VERSION ""

NS_ :

BS_:

BU_:

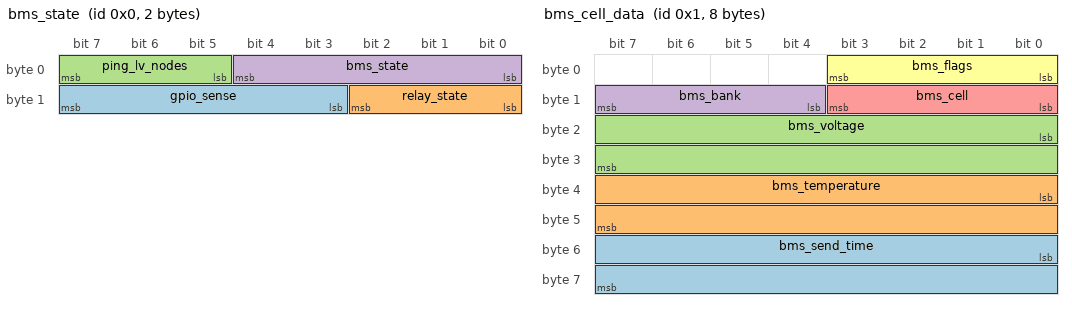
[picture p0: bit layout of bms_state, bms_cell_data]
BO_ 0 bms_state: 2 Vector__XXX
 SG_ gpio_sense : 11|5@1+ (1,0) [0|0] "" Vector__XXX
 SG_ relay_state : 8|3@1+ (1,0) [0|0] "" Vector__XXX
 SG_ ping_lv_nodes : 5|3@1+ (1,0) [0|0] "" Vector__XXX
 SG_ bms_state : 0|5@1+ (1,0) [0|0] "" Vector__XXX

BO_ 1 bms_cell_data: 8 Vector__XXX
 SG_ bms_send_time : 48|16@1+ (1,0) [0|0] "" Vector__XXX
 SG_ bms_temperature : 32|16@1- (1,0) [0|0] "" Vector__XXX
 SG_ bms_voltage : 16|16@1+ (1,0) [0|0] "" Vector__XXX
 SG_ bms_bank : 12|4@1+ (1,0) [0|0] "" Vector__XXX
 SG_ bms_cell : 8|4@1+ (1,0) [0|0] "" Vector__XXX
 SG_ bms_flags : 0|4@1+ (1,0) [0|0] "" Vector__XXX

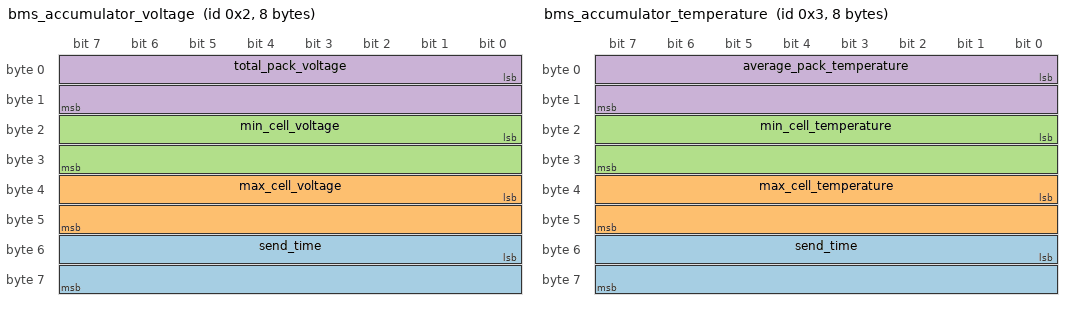
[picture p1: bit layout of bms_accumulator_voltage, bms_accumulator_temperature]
BO_ 2 bms_accumulator_voltage: 8 Vector__XXX
 SG_ send_time : 48|16@1+ (1,0) [0|0] "" Vector__XXX
 SG_ max_cell_voltage : 32|16@1+ (1,0) [0|0] "" Vector__XXX
 SG_ min_cell_voltage : 16|16@1+ (1,0) [0|0] "" Vector__XXX
 SG_ total_pack_voltage : 0|16@1+ (1,0) [0|0] "" Vector__XXX

BO_ 3 bms_accumulator_temperature: 8 Vector__XXX
 SG_ send_time : 48|16@1+ (1,0) [0|0] "" Vector__XXX
 SG_ max_cell_temperature : 32|16@1- (1,0) [0|0] "" Vector__XXX
 SG_ min_cell_temperature : 16|16@1- (1,0) [0|0] "" Vector__XXX
 SG_ average_pack_temperature : 0|16@1- (1,0) [0|0] "" Vector__XXX

BO_ 4 accumulator_faults: 1 Vector__XXX
 SG_ imd_fault : 1|1@1+ (1,0) [0|0] "" Vector__XXX
 SG_ bms_fault : 0|1@1+ (1,0) [0|0] "" Vector__XXX

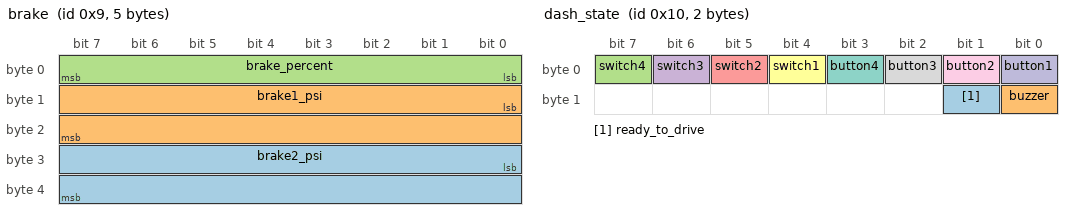
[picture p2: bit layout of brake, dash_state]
BO_ 9 brake: 5 Vector__XXX
 SG_ brake2_psi : 24|16@1+ (1,0) [0|0] "" Vector__XXX
 SG_ brake1_psi : 8|16@1+ (1,0) [0|0] "" Vector__XXX
 SG_ brake_percent : 0|8@1+ (1,0) [0|0] "" Vector__XXX

BO_ 10 bspd_state: 1 Vector__XXX
 SG_ bspd_state : 0|8@1+ (1,0) [0|0] "" Vector__XXX

BO_ 16 dash_state: 2 Vector__XXX
 SG_ ready_to_drive : 9|1@1+ (1,0) [0|0] "" Vector__XXX
 SG_ buzzer : 8|1@1+ (1,0) [0|0] "" Vector__XXX
 SG_ switch4 : 7|1@1+ (1,0) [0|0] "" Vector__XXX
 SG_ switch3 : 6|1@1+ (1,0) [0|0] "" Vector__XXX
 SG_ switch2 : 5|1@1+ (1,0) [0|0] "" Vector__XXX
 SG_ switch1 : 4|1@1+ (1,0) [0|0] "" Vector__XXX
 SG_ button4 : 3|1@1+ (1,0) [0|0] "" Vector__XXX
 SG_ button3 : 2|1@1+ (1,0) [0|0] "" Vector__XXX
 SG_ button2 : 1|1@1+ (1,0) [0|0] "" Vector__XXX
 SG_ button1 : 0|1@1+ (1,0) [0|0] "" Vector__XXX

BO_ 22 lvpdb_lv_24v_bus_and_12v_bus_vol: 4 Vector__XXX
 SG_ lv_12v_voltage : 16|16@1+ (1,0) [0|0] "" Vector__XXX
 SG_ lv_24v_voltage : 0|16@1+ (1,0) [0|0] "" Vector__XXX

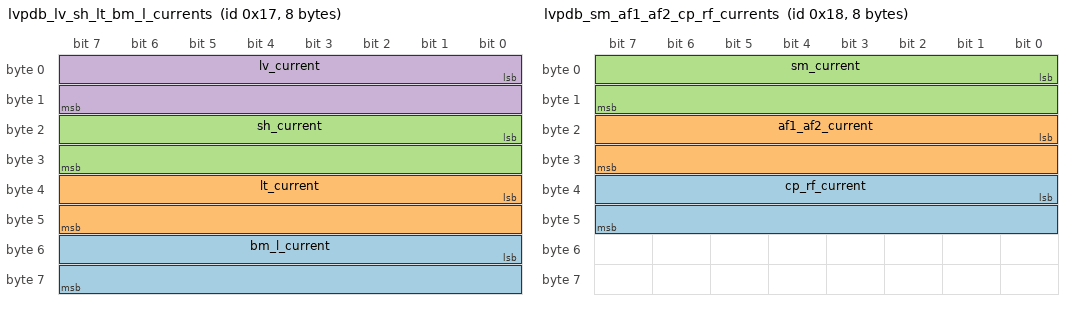
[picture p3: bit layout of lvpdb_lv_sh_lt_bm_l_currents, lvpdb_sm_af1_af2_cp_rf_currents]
BO_ 23 lvpdb_lv_sh_lt_bm_l_currents: 8 Vector__XXX
 SG_ bm_l_current : 48|16@1+ (1,0) [0|0] "" Vector__XXX
 SG_ lt_current : 32|16@1+ (1,0) [0|0] "" Vector__XXX
 SG_ sh_current : 16|16@1+ (1,0) [0|0] "" Vector__XXX
 SG_ lv_current : 0|16@1+ (1,0) [0|0] "" Vector__XXX

BO_ 24 lvpdb_sm_af1_af2_cp_rf_currents: 8 Vector__XXX
 SG_ cp_rf_current : 32|16@1+ (1,0) [0|0] "" Vector__XXX
 SG_ af1_af2_current : 16|16@1+ (1,0) [0|0] "" Vector__XXX
 SG_ sm_current : 0|16@1+ (1,0) [0|0] "" Vector__XXX

BO_ 30 linear_potentiometer_front: 4 Vector__XXX
 SG_ linear_potrentiometer_2_front : 16|16@1+ (1,0) [0|0] "" Vector__XXX
 SG_ linear_potrentiometer_1_front : 0|16@1+ (1,0) [0|0] "" Vector__XXX

BO_ 31 linear_potentiometer_rear: 4 Vector__XXX
 SG_ linear_potrentiometer_2_rear : 16|16@1+ (1,0) [0|0] "" Vector__XXX
 SG_ linear_potrentiometer_1_rear : 0|16@1+ (1,0) [0|0] "" Vector__XXX

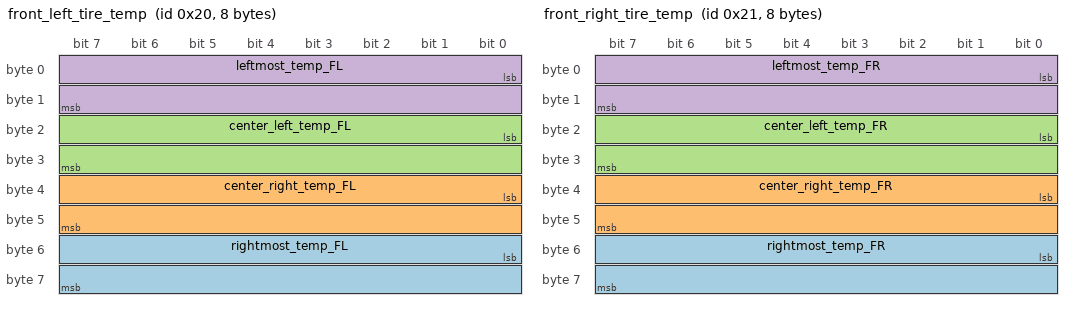
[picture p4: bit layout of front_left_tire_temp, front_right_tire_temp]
BO_ 32 front_left_tire_temp: 8 Vector__XXX
 SG_ rightmost_temp_FL : 48|16@1+ (1,0) [0|0] "" Vector__XXX
 SG_ center_right_temp_FL : 32|16@1+ (1,0) [0|0] "" Vector__XXX
 SG_ center_left_temp_FL : 16|16@1+ (1,0) [0|0] "" Vector__XXX
 SG_ leftmost_temp_FL : 0|16@1+ (1,0) [0|0] "" Vector__XXX

BO_ 33 front_right_tire_temp: 8 Vector__XXX
 SG_ rightmost_temp_FR : 48|16@1+ (1,0) [0|0] "" Vector__XXX
 SG_ center_right_temp_FR : 32|16@1+ (1,0) [0|0] "" Vector__XXX
 SG_ center_left_temp_FR : 16|16@1+ (1,0) [0|0] "" Vector__XXX
 SG_ leftmost_temp_FR : 0|16@1+ (1,0) [0|0] "" Vector__XXX

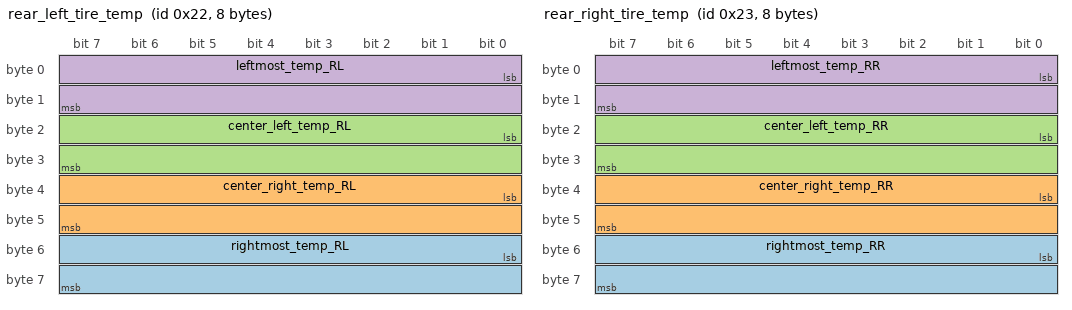
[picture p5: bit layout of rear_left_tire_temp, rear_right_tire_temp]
BO_ 34 rear_left_tire_temp: 8 Vector__XXX
 SG_ rightmost_temp_RL : 48|16@1+ (1,0) [0|0] "" Vector__XXX
 SG_ center_right_temp_RL : 32|16@1+ (1,0) [0|0] "" Vector__XXX
 SG_ center_left_temp_RL : 16|16@1+ (1,0) [0|0] "" Vector__XXX
 SG_ leftmost_temp_RL : 0|16@1+ (1,0) [0|0] "" Vector__XXX

BO_ 35 rear_right_tire_temp: 8 Vector__XXX
 SG_ rightmost_temp_RR : 48|16@1+ (1,0) [0|0] "" Vector__XXX
 SG_ center_right_temp_RR : 32|16@1+ (1,0) [0|0] "" Vector__XXX
 SG_ center_left_temp_RR : 16|16@1+ (1,0) [0|0] "" Vector__XXX
 SG_ leftmost_temp_RR : 0|16@1+ (1,0) [0|0] "" Vector__XXX

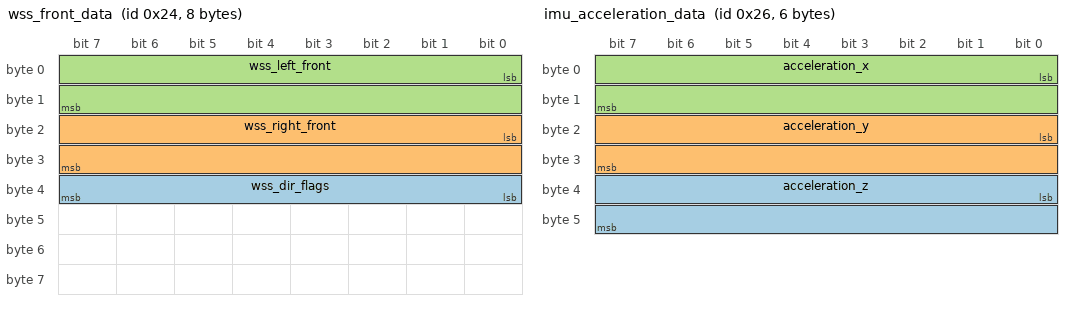
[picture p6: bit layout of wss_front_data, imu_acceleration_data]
BO_ 36 wss_front_data: 8 Vector__XXX
 SG_ wss_dir_flags : 32|8@1+ (1,0) [0|0] "" Vector__XXX
 SG_ wss_right_front : 16|16@1+ (0.1,0) [0|0] "RPM" Vector__XXX
 SG_ wss_left_front : 0|16@1+ (0.1,0) [0|0] "RPM" Vector__XXX

BO_ 37 wss_rear_data: 8 Vector__XXX
 SG_ wss_left_rear : 32|32@1+ (1,0) [0|0] "" Vector__XXX
 SG_ wss_right_rear : 0|32@1+ (1,0) [0|0] "" Vector__XXX

BO_ 38 imu_acceleration_data: 6 Vector__XXX
 SG_ acceleration_z : 32|16@1- (0.061,0) [0|0] "mg" Vector__XXX
 SG_ acceleration_y : 16|16@1- (0.061,0) [0|0] "mg" Vector__XXX
 SG_ acceleration_x : 0|16@1- (0.061,0) [0|0] "mg" Vector__XXX

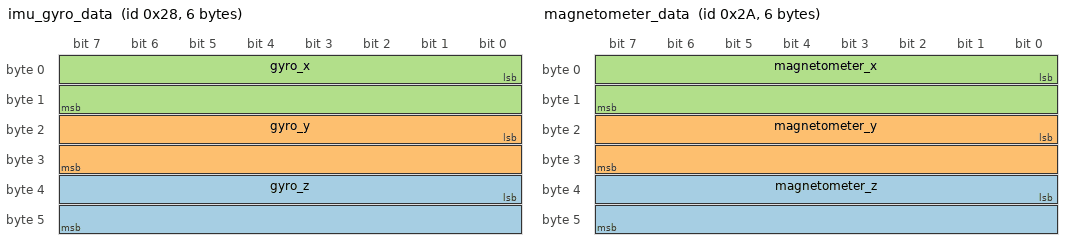
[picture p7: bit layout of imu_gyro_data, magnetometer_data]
BO_ 40 imu_gyro_data: 6 Vector__XXX
 SG_ gyro_z : 32|16@1- (70,0) [0|0] "mdps" Vector__XXX
 SG_ gyro_y : 16|16@1- (70,0) [0|0] "mdps" Vector__XXX
 SG_ gyro_x : 0|16@1- (70,0) [0|0] "mdps" Vector__XXX

BO_ 42 magnetometer_data: 6 Vector__XXX
 SG_ magnetometer_z : 32|16@1- (0.5844,0) [0|0] "mG" Vector__XXX
 SG_ magnetometer_y : 16|16@1- (0.5844,0) [0|0] "mG" Vector__XXX
 SG_ magnetometer_x : 0|16@1- (0.5844,0) [0|0] "mG" Vector__XXX

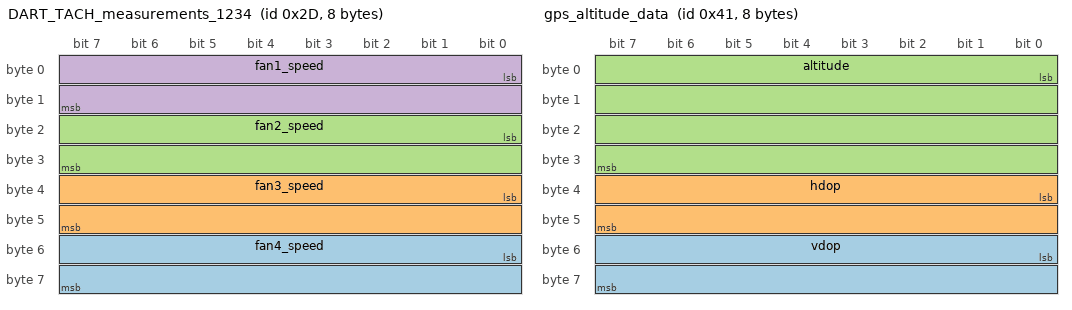
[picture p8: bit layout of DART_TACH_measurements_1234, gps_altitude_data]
BO_ 45 DART_TACH_measurements_1234: 8 Vector__XXX
 SG_ fan4_speed : 48|16@1+ (1,0) [0|0] "" Vector__XXX
 SG_ fan3_speed : 32|16@1+ (1,0) [0|0] "" Vector__XXX
 SG_ fan2_speed : 16|16@1+ (1,0) [0|0] "" Vector__XXX
 SG_ fan1_speed : 0|16@1+ (1,0) [0|0] "" Vector__XXX

BO_ 46 DART_TACH_measurements_5: 2 Vector__XXX
 SG_ fan5_speed : 0|16@1+ (1,0) [0|0] "" Vector__XXX

BO_ 52 bbb_tps: 4 Vector__XXX
 SG_ current : 16|16@1+ (1,0) [0|0] "" Vector__XXX
 SG_ voltage : 0|16@1+ (1,0) [0|0] "" Vector__XXX

BO_ 53 pcu_tps: 4 Vector__XXX
 SG_ current : 16|16@1+ (1,0) [0|0] "" Vector__XXX
 SG_ voltage : 0|16@1+ (1,0) [0|0] "" Vector__XXX

BO_ 54 dash_tps: 4 Vector__XXX
 SG_ current : 16|16@1+ (1,0) [0|0] "" Vector__XXX
 SG_ voltage : 0|16@1+ (1,0) [0|0] "" Vector__XXX

BO_ 55 dcu_tps: 4 Vector__XXX
 SG_ current : 16|16@1+ (1,0) [0|0] "" Vector__XXX
 SG_ voltage : 0|16@1+ (1,0) [0|0] "" Vector__XXX

BO_ 64 gps_pos_data: 8 Vector__XXX
 SG_ longitude : 32|32@1- (1e-07,0) [0|0] "deg" Vector__XXX
 SG_ latitude : 0|32@1- (1e-07,0) [0|0] "deg" Vector__XXX

BO_ 65 gps_altitude_data: 8 Vector__XXX
 SG_ vdop : 48|16@1+ (0.01,0) [0|0] "" Vector__XXX
 SG_ hdop : 32|16@1+ (0.01,0) [0|0] "" Vector__XXX
 SG_ altitude : 0|32@1- (0.01,0) [0|0] "m" Vector__XXX

BO_ 66 gps_motion_data: 4 Vector__XXX
 SG_ course : 16|16@1+ (0.01,0) [0|0] "deg" Vector__XXX
 SG_ speed : 0|16@1+ (0.01,0) [0|0] "km/h" Vector__XXX

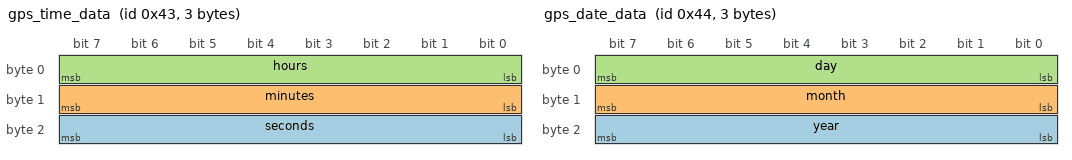
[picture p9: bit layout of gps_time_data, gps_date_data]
BO_ 67 gps_time_data: 3 Vector__XXX
 SG_ seconds : 16|8@1- (1,0) [0|0] "" Vector__XXX
 SG_ minutes : 8|8@1- (1,0) [0|0] "" Vector__XXX
 SG_ hours : 0|8@1- (1,0) [0|0] "" Vector__XXX

BO_ 68 gps_date_data: 3 Vector__XXX
 SG_ year : 16|8@1- (1,0) [0|0] "" Vector__XXX
 SG_ month : 8|8@1- (1,0) [0|0] "" Vector__XXX
 SG_ day : 0|8@1- (1,0) [0|0] "" Vector__XXX

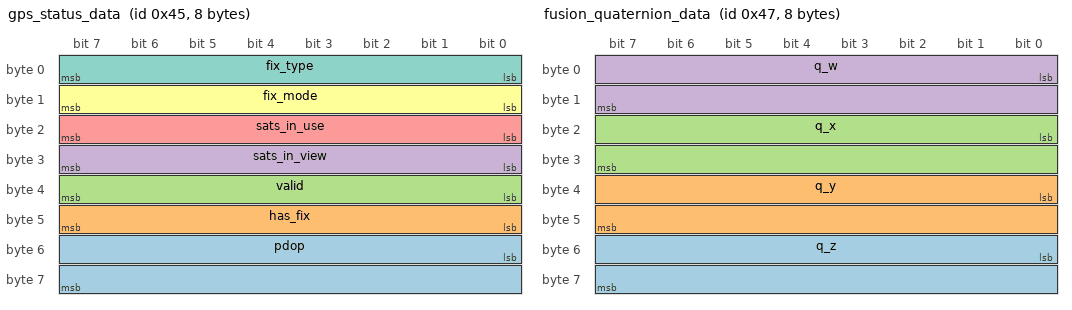
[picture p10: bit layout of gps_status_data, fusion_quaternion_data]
BO_ 69 gps_status_data: 8 Vector__XXX
 SG_ pdop : 48|16@1+ (0.01,0) [0|0] "" Vector__XXX
 SG_ has_fix : 40|8@1+ (1,0) [0|0] "" Vector__XXX
 SG_ valid : 32|8@1+ (1,0) [0|0] "" Vector__XXX
 SG_ sats_in_view : 24|8@1+ (1,0) [0|0] "" Vector__XXX
 SG_ sats_in_use : 16|8@1+ (1,0) [0|0] "" Vector__XXX
 SG_ fix_mode : 8|8@1+ (1,0) [0|0] "" Vector__XXX
 SG_ fix_type : 0|8@1+ (1,0) [0|0] "" Vector__XXX

BO_ 71 fusion_quaternion_data: 8 Vector__XXX
 SG_ q_z : 48|16@1- (3.051850947599719e-05,0) [0|0] "" Vector__XXX
 SG_ q_y : 32|16@1- (3.051850947599719e-05,0) [0|0] "" Vector__XXX
 SG_ q_x : 16|16@1- (3.051850947599719e-05,0) [0|0] "" Vector__XXX
 SG_ q_w : 0|16@1- (3.051850947599719e-05,0) [0|0] "" Vector__XXX

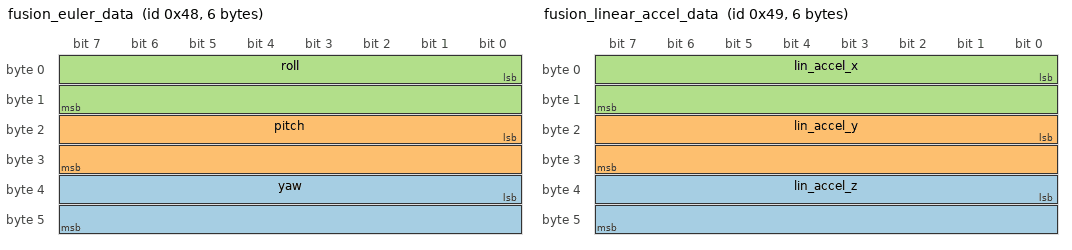
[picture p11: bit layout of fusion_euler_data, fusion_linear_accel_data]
BO_ 72 fusion_euler_data: 6 Vector__XXX
 SG_ yaw : 32|16@1- (0.01,0) [0|0] "deg" Vector__XXX
 SG_ pitch : 16|16@1- (0.01,0) [0|0] "deg" Vector__XXX
 SG_ roll : 0|16@1- (0.01,0) [0|0] "deg" Vector__XXX

BO_ 73 fusion_linear_accel_data: 6 Vector__XXX
 SG_ lin_accel_z : 32|16@1- (1,0) [0|0] "mg" Vector__XXX
 SG_ lin_accel_y : 16|16@1- (1,0) [0|0] "mg" Vector__XXX
 SG_ lin_accel_x : 0|16@1- (1,0) [0|0] "mg" Vector__XXX

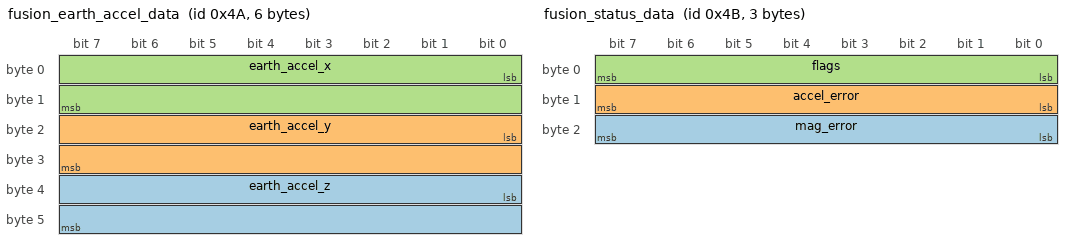
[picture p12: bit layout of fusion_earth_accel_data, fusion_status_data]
BO_ 74 fusion_earth_accel_data: 6 Vector__XXX
 SG_ earth_accel_z : 32|16@1- (1,0) [0|0] "mg" Vector__XXX
 SG_ earth_accel_y : 16|16@1- (1,0) [0|0] "mg" Vector__XXX
 SG_ earth_accel_x : 0|16@1- (1,0) [0|0] "mg" Vector__XXX

BO_ 75 fusion_status_data: 3 Vector__XXX
 SG_ mag_error : 16|8@1+ (0.1,0) [0|0] "deg" Vector__XXX
 SG_ accel_error : 8|8@1+ (0.1,0) [0|0] "deg" Vector__XXX
 SG_ flags : 0|8@1+ (1,0) [0|0] "" Vector__XXX

BO_ 76 sensor_temps_data: 4 Vector__XXX
 SG_ mag_temp : 16|16@1- (0.01,0) [0|0] "degC" Vector__XXX
 SG_ imu_temp : 0|16@1- (0.01,0) [0|0] "degC" Vector__XXX

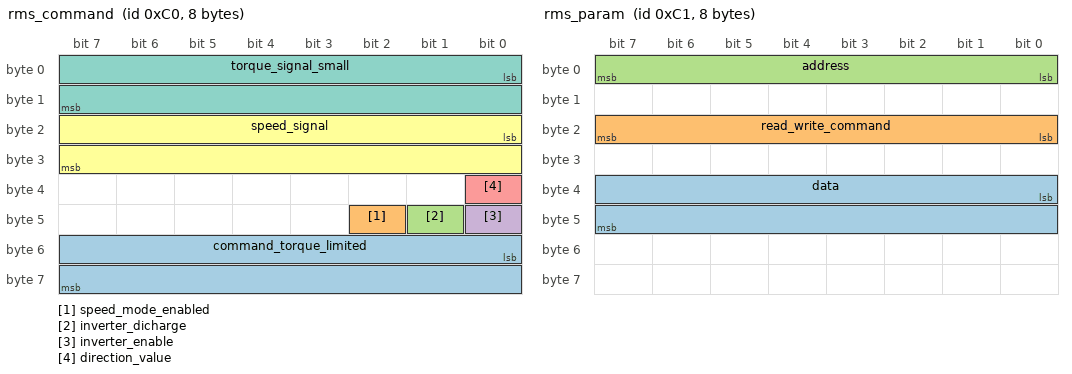
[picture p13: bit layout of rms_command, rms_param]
BO_ 192 rms_command: 8 Vector__XXX
 SG_ command_torque_limited : 48|16@1+ (1,0) [0|0] "" Vector__XXX
 SG_ speed_mode_enabled : 42|1@1+ (1,0) [0|0] "" Vector__XXX
 SG_ inverter_dicharge : 41|1@1+ (1,0) [0|0] "" Vector__XXX
 SG_ inverter_enable : 40|1@1+ (1,0) [0|0] "" Vector__XXX
 SG_ direction_value : 32|1@1+ (1,0) [0|0] "" Vector__XXX
 SG_ speed_signal : 16|16@1+ (1,0) [0|0] "" Vector__XXX
 SG_ torque_signal_small : 0|16@1+ (1,0) [0|0] "" Vector__XXX

BO_ 193 rms_param: 8 Vector__XXX
 SG_ data : 32|16@1+ (1,0) [0|0] "" Vector__XXX
 SG_ read_write_command : 16|8@1+ (1,0) [0|0] "" Vector__XXX
 SG_ address : 0|8@1+ (1,0) [0|0] "" Vector__XXX

BO_ 208 pcu_heartbeat: 8 Vector__XXX
 SG_ error63 : 63|1@1+ (1,0) [0|0] "" Vector__XXX
 SG_ error62 : 62|1@1+ (1,0) [0|0] "" Vector__XXX
 SG_ error61 : 61|1@1+ (1,0) [0|0] "" Vector__XXX
 SG_ error60 : 60|1@1+ (1,0) [0|0] "" Vector__XXX
 SG_ error59 : 59|1@1+ (1,0) [0|0] "" Vector__XXX
 SG_ error58 : 58|1@1+ (1,0) [0|0] "" Vector__XXX
 SG_ error57 : 57|1@1+ (1,0) [0|0] "" Vector__XXX
 SG_ error56 : 56|1@1+ (1,0) [0|0] "" Vector__XXX
 SG_ error55 : 55|1@1+ (1,0) [0|0] "" Vector__XXX
 SG_ error54 : 54|1@1+ (1,0) [0|0] "" Vector__XXX
 SG_ error53 : 53|1@1+ (1,0) [0|0] "" Vector__XXX
 SG_ error52 : 52|1@1+ (1,0) [0|0] "" Vector__XXX
 SG_ error51 : 51|1@1+ (1,0) [0|0] "" Vector__XXX
 SG_ error50 : 50|1@1+ (1,0) [0|0] "" Vector__XXX
 SG_ error49 : 49|1@1+ (1,0) [0|0] "" Vector__XXX
 SG_ error48 : 48|1@1+ (1,0) [0|0] "" Vector__XXX
 SG_ error47 : 47|1@1+ (1,0) [0|0] "" Vector__XXX
 SG_ error46 : 46|1@1+ (1,0) [0|0] "" Vector__XXX
 SG_ error45 : 45|1@1+ (1,0) [0|0] "" Vector__XXX
 SG_ error44 : 44|1@1+ (1,0) [0|0] "" Vector__XXX
 SG_ error43 : 43|1@1+ (1,0) [0|0] "" Vector__XXX
 SG_ error42 : 42|1@1+ (1,0) [0|0] "" Vector__XXX
 SG_ error41 : 41|1@1+ (1,0) [0|0] "" Vector__XXX
 SG_ error40 : 40|1@1+ (1,0) [0|0] "" Vector__XXX
 SG_ error39 : 39|1@1+ (1,0) [0|0] "" Vector__XXX
 SG_ error38 : 38|1@1+ (1,0) [0|0] "" Vector__XXX
 SG_ error37 : 37|1@1+ (1,0) [0|0] "" Vector__XXX
 SG_ error36 : 36|1@1+ (1,0) [0|0] "" Vector__XXX
 SG_ error35 : 35|1@1+ (1,0) [0|0] "" Vector__XXX
 SG_ error34 : 34|1@1+ (1,0) [0|0] "" Vector__XXX
 SG_ error33 : 33|1@1+ (1,0) [0|0] "" Vector__XXX
 SG_ error32 : 32|1@1+ (1,0) [0|0] "" Vector__XXX
 SG_ error31 : 31|1@1+ (1,0) [0|0] "" Vector__XXX
 SG_ error30 : 30|1@1+ (1,0) [0|0] "" Vector__XXX
 SG_ error29 : 29|1@1+ (1,0) [0|0] "" Vector__XXX
 SG_ error28 : 28|1@1+ (1,0) [0|0] "" Vector__XXX
 SG_ error27 : 27|1@1+ (1,0) [0|0] "" Vector__XXX
 SG_ error26 : 26|1@1+ (1,0) [0|0] "" Vector__XXX
 SG_ error25 : 25|1@1+ (1,0) [0|0] "" Vector__XXX
 SG_ error24 : 24|1@1+ (1,0) [0|0] "" Vector__XXX
 SG_ error23 : 23|1@1+ (1,0) [0|0] "" Vector__XXX
 SG_ error22 : 22|1@1+ (1,0) [0|0] "" Vector__XXX
 SG_ error21 : 21|1@1+ (1,0) [0|0] "" Vector__XXX
 SG_ error20 : 20|1@1+ (1,0) [0|0] "" Vector__XXX
 SG_ error19 : 19|1@1+ (1,0) [0|0] "" Vector__XXX
 SG_ error18 : 18|1@1+ (1,0) [0|0] "" Vector__XXX
 SG_ error17 : 17|1@1+ (1,0) [0|0] "" Vector__XXX
 SG_ error16 : 16|1@1+ (1,0) [0|0] "" Vector__XXX
 SG_ error15 : 15|1@1+ (1,0) [0|0] "" Vector__XXX
 SG_ error14 : 14|1@1+ (1,0) [0|0] "" Vector__XXX
 SG_ error13 : 13|1@1+ (1,0) [0|0] "" Vector__XXX
 SG_ error12 : 12|1@1+ (1,0) [0|0] "" Vector__XXX
 SG_ error11 : 11|1@1+ (1,0) [0|0] "" Vector__XXX
 SG_ error10 : 10|1@1+ (1,0) [0|0] "" Vector__XXX
 SG_ error9 : 9|1@1+ (1,0) [0|0] "" Vector__XXX
 SG_ error8 : 8|1@1+ (1,0) [0|0] "" Vector__XXX
 SG_ error7 : 7|1@1+ (1,0) [0|0] "" Vector__XXX
 SG_ error6 : 6|1@1+ (1,0) [0|0] "" Vector__XXX
 SG_ error5 : 5|1@1+ (1,0) [0|0] "" Vector__XXX
 SG_ error4 : 4|1@1+ (1,0) [0|0] "" Vector__XXX
 SG_ error3 : 3|1@1+ (1,0) [0|0] "" Vector__XXX
 SG_ error2 : 2|1@1+ (1,0) [0|0] "" Vector__XXX
 SG_ error1 : 1|1@1+ (1,0) [0|0] "" Vector__XXX
 SG_ error0 : 0|1@1+ (1,0) [0|0] "" Vector__XXX

BO_ 209 dash_heartbeat: 8 Vector__XXX
 SG_ error63 : 63|1@1+ (1,0) [0|0] "" Vector__XXX
 SG_ error62 : 62|1@1+ (1,0) [0|0] "" Vector__XXX
 SG_ error61 : 61|1@1+ (1,0) [0|0] "" Vector__XXX
 SG_ error60 : 60|1@1+ (1,0) [0|0] "" Vector__XXX
 SG_ error59 : 59|1@1+ (1,0) [0|0] "" Vector__XXX
 SG_ error58 : 58|1@1+ (1,0) [0|0] "" Vector__XXX
 SG_ error57 : 57|1@1+ (1,0) [0|0] "" Vector__XXX
 SG_ error56 : 56|1@1+ (1,0) [0|0] "" Vector__XXX
 SG_ error55 : 55|1@1+ (1,0) [0|0] "" Vector__XXX
 SG_ error54 : 54|1@1+ (1,0) [0|0] "" Vector__XXX
 SG_ error53 : 53|1@1+ (1,0) [0|0] "" Vector__XXX
 SG_ error52 : 52|1@1+ (1,0) [0|0] "" Vector__XXX
 SG_ error51 : 51|1@1+ (1,0) [0|0] "" Vector__XXX
 SG_ error50 : 50|1@1+ (1,0) [0|0] "" Vector__XXX
 SG_ error49 : 49|1@1+ (1,0) [0|0] "" Vector__XXX
 SG_ error48 : 48|1@1+ (1,0) [0|0] "" Vector__XXX
 SG_ error47 : 47|1@1+ (1,0) [0|0] "" Vector__XXX
 SG_ error46 : 46|1@1+ (1,0) [0|0] "" Vector__XXX
 SG_ error45 : 45|1@1+ (1,0) [0|0] "" Vector__XXX
 SG_ error44 : 44|1@1+ (1,0) [0|0] "" Vector__XXX
 SG_ error43 : 43|1@1+ (1,0) [0|0] "" Vector__XXX
 SG_ error42 : 42|1@1+ (1,0) [0|0] "" Vector__XXX
 SG_ error41 : 41|1@1+ (1,0) [0|0] "" Vector__XXX
 SG_ error40 : 40|1@1+ (1,0) [0|0] "" Vector__XXX
 SG_ error39 : 39|1@1+ (1,0) [0|0] "" Vector__XXX
 SG_ error38 : 38|1@1+ (1,0) [0|0] "" Vector__XXX
 SG_ error37 : 37|1@1+ (1,0) [0|0] "" Vector__XXX
 SG_ error36 : 36|1@1+ (1,0) [0|0] "" Vector__XXX
 SG_ error35 : 35|1@1+ (1,0) [0|0] "" Vector__XXX
 SG_ error34 : 34|1@1+ (1,0) [0|0] "" Vector__XXX
 SG_ error33 : 33|1@1+ (1,0) [0|0] "" Vector__XXX
 SG_ error32 : 32|1@1+ (1,0) [0|0] "" Vector__XXX
 SG_ error31 : 31|1@1+ (1,0) [0|0] "" Vector__XXX
 SG_ error30 : 30|1@1+ (1,0) [0|0] "" Vector__XXX
 SG_ error29 : 29|1@1+ (1,0) [0|0] "" Vector__XXX
 SG_ error28 : 28|1@1+ (1,0) [0|0] "" Vector__XXX
 SG_ error27 : 27|1@1+ (1,0) [0|0] "" Vector__XXX
 SG_ error26 : 26|1@1+ (1,0) [0|0] "" Vector__XXX
 SG_ error25 : 25|1@1+ (1,0) [0|0] "" Vector__XXX
 SG_ error24 : 24|1@1+ (1,0) [0|0] "" Vector__XXX
 SG_ error23 : 23|1@1+ (1,0) [0|0] "" Vector__XXX
 SG_ error22 : 22|1@1+ (1,0) [0|0] "" Vector__XXX
 SG_ error21 : 21|1@1+ (1,0) [0|0] "" Vector__XXX
 SG_ error20 : 20|1@1+ (1,0) [0|0] "" Vector__XXX
 SG_ error19 : 19|1@1+ (1,0) [0|0] "" Vector__XXX
 SG_ error18 : 18|1@1+ (1,0) [0|0] "" Vector__XXX
 SG_ error17 : 17|1@1+ (1,0) [0|0] "" Vector__XXX
 SG_ error16 : 16|1@1+ (1,0) [0|0] "" Vector__XXX
 SG_ error15 : 15|1@1+ (1,0) [0|0] "" Vector__XXX
 SG_ error14 : 14|1@1+ (1,0) [0|0] "" Vector__XXX
 SG_ error13 : 13|1@1+ (1,0) [0|0] "" Vector__XXX
 SG_ error12 : 12|1@1+ (1,0) [0|0] "" Vector__XXX
 SG_ error11 : 11|1@1+ (1,0) [0|0] "" Vector__XXX
 SG_ error10 : 10|1@1+ (1,0) [0|0] "" Vector__XXX
 SG_ error9 : 9|1@1+ (1,0) [0|0] "" Vector__XXX
 SG_ error8 : 8|1@1+ (1,0) [0|0] "" Vector__XXX
 SG_ error7 : 7|1@1+ (1,0) [0|0] "" Vector__XXX
 SG_ error6 : 6|1@1+ (1,0) [0|0] "" Vector__XXX
 SG_ error5 : 5|1@1+ (1,0) [0|0] "" Vector__XXX
 SG_ error4 : 4|1@1+ (1,0) [0|0] "" Vector__XXX
 SG_ error3 : 3|1@1+ (1,0) [0|0] "" Vector__XXX
 SG_ error2 : 2|1@1+ (1,0) [0|0] "" Vector__XXX
 SG_ error1 : 1|1@1+ (1,0) [0|0] "" Vector__XXX
 SG_ error0 : 0|1@1+ (1,0) [0|0] "" Vector__XXX

BO_ 210 lvpdb_heartbeat: 8 Vector__XXX
 SG_ error63 : 63|1@1+ (1,0) [0|0] "" Vector__XXX
 SG_ error62 : 62|1@1+ (1,0) [0|0] "" Vector__XXX
 SG_ error61 : 61|1@1+ (1,0) [0|0] "" Vector__XXX
 SG_ error60 : 60|1@1+ (1,0) [0|0] "" Vector__XXX
 SG_ error59 : 59|1@1+ (1,0) [0|0] "" Vector__XXX
 SG_ error58 : 58|1@1+ (1,0) [0|0] "" Vector__XXX
 SG_ error57 : 57|1@1+ (1,0) [0|0] "" Vector__XXX
 SG_ error56 : 56|1@1+ (1,0) [0|0] "" Vector__XXX
 SG_ error55 : 55|1@1+ (1,0) [0|0] "" Vector__XXX
 SG_ error54 : 54|1@1+ (1,0) [0|0] "" Vector__XXX
 SG_ error53 : 53|1@1+ (1,0) [0|0] "" Vector__XXX
 SG_ error52 : 52|1@1+ (1,0) [0|0] "" Vector__XXX
 SG_ error51 : 51|1@1+ (1,0) [0|0] "" Vector__XXX
 SG_ error50 : 50|1@1+ (1,0) [0|0] "" Vector__XXX
 SG_ error49 : 49|1@1+ (1,0) [0|0] "" Vector__XXX
 SG_ error48 : 48|1@1+ (1,0) [0|0] "" Vector__XXX
 SG_ error47 : 47|1@1+ (1,0) [0|0] "" Vector__XXX
 SG_ error46 : 46|1@1+ (1,0) [0|0] "" Vector__XXX
 SG_ error45 : 45|1@1+ (1,0) [0|0] "" Vector__XXX
 SG_ error44 : 44|1@1+ (1,0) [0|0] "" Vector__XXX
 SG_ error43 : 43|1@1+ (1,0) [0|0] "" Vector__XXX
 SG_ error42 : 42|1@1+ (1,0) [0|0] "" Vector__XXX
 SG_ error41 : 41|1@1+ (1,0) [0|0] "" Vector__XXX
 SG_ error40 : 40|1@1+ (1,0) [0|0] "" Vector__XXX
 SG_ error39 : 39|1@1+ (1,0) [0|0] "" Vector__XXX
 SG_ error38 : 38|1@1+ (1,0) [0|0] "" Vector__XXX
 SG_ error37 : 37|1@1+ (1,0) [0|0] "" Vector__XXX
 SG_ error36 : 36|1@1+ (1,0) [0|0] "" Vector__XXX
 SG_ error35 : 35|1@1+ (1,0) [0|0] "" Vector__XXX
 SG_ error34 : 34|1@1+ (1,0) [0|0] "" Vector__XXX
 SG_ error33 : 33|1@1+ (1,0) [0|0] "" Vector__XXX
 SG_ error32 : 32|1@1+ (1,0) [0|0] "" Vector__XXX
 SG_ error31 : 31|1@1+ (1,0) [0|0] "" Vector__XXX
 SG_ error30 : 30|1@1+ (1,0) [0|0] "" Vector__XXX
 SG_ error29 : 29|1@1+ (1,0) [0|0] "" Vector__XXX
 SG_ error28 : 28|1@1+ (1,0) [0|0] "" Vector__XXX
 SG_ error27 : 27|1@1+ (1,0) [0|0] "" Vector__XXX
 SG_ error26 : 26|1@1+ (1,0) [0|0] "" Vector__XXX
 SG_ error25 : 25|1@1+ (1,0) [0|0] "" Vector__XXX
 SG_ error24 : 24|1@1+ (1,0) [0|0] "" Vector__XXX
 SG_ error23 : 23|1@1+ (1,0) [0|0] "" Vector__XXX
 SG_ error22 : 22|1@1+ (1,0) [0|0] "" Vector__XXX
 SG_ error21 : 21|1@1+ (1,0) [0|0] "" Vector__XXX
 SG_ error20 : 20|1@1+ (1,0) [0|0] "" Vector__XXX
 SG_ error19 : 19|1@1+ (1,0) [0|0] "" Vector__XXX
 SG_ error18 : 18|1@1+ (1,0) [0|0] "" Vector__XXX
 SG_ error17 : 17|1@1+ (1,0) [0|0] "" Vector__XXX
 SG_ error16 : 16|1@1+ (1,0) [0|0] "" Vector__XXX
 SG_ error15 : 15|1@1+ (1,0) [0|0] "" Vector__XXX
 SG_ error14 : 14|1@1+ (1,0) [0|0] "" Vector__XXX
 SG_ error13 : 13|1@1+ (1,0) [0|0] "" Vector__XXX
 SG_ error12 : 12|1@1+ (1,0) [0|0] "" Vector__XXX
 SG_ error11 : 11|1@1+ (1,0) [0|0] "" Vector__XXX
 SG_ error10 : 10|1@1+ (1,0) [0|0] "" Vector__XXX
 SG_ error9 : 9|1@1+ (1,0) [0|0] "" Vector__XXX
 SG_ error8 : 8|1@1+ (1,0) [0|0] "" Vector__XXX
 SG_ error7 : 7|1@1+ (1,0) [0|0] "" Vector__XXX
 SG_ error6 : 6|1@1+ (1,0) [0|0] "" Vector__XXX
 SG_ error5 : 5|1@1+ (1,0) [0|0] "" Vector__XXX
 SG_ error4 : 4|1@1+ (1,0) [0|0] "" Vector__XXX
 SG_ error3 : 3|1@1+ (1,0) [0|0] "" Vector__XXX
 SG_ error2 : 2|1@1+ (1,0) [0|0] "" Vector__XXX
 SG_ error1 : 1|1@1+ (1,0) [0|0] "" Vector__XXX
 SG_ error0 : 0|1@1+ (1,0) [0|0] "" Vector__XXX

BO_ 211 dcu_heartbeat: 8 Vector__XXX
 SG_ error63 : 63|1@1+ (1,0) [0|0] "" Vector__XXX
 SG_ error62 : 62|1@1+ (1,0) [0|0] "" Vector__XXX
 SG_ error61 : 61|1@1+ (1,0) [0|0] "" Vector__XXX
 SG_ error60 : 60|1@1+ (1,0) [0|0] "" Vector__XXX
 SG_ error59 : 59|1@1+ (1,0) [0|0] "" Vector__XXX
 SG_ error58 : 58|1@1+ (1,0) [0|0] "" Vector__XXX
 SG_ error57 : 57|1@1+ (1,0) [0|0] "" Vector__XXX
 SG_ error56 : 56|1@1+ (1,0) [0|0] "" Vector__XXX
 SG_ error55 : 55|1@1+ (1,0) [0|0] "" Vector__XXX
 SG_ error54 : 54|1@1+ (1,0) [0|0] "" Vector__XXX
 SG_ error53 : 53|1@1+ (1,0) [0|0] "" Vector__XXX
 SG_ error52 : 52|1@1+ (1,0) [0|0] "" Vector__XXX
 SG_ error51 : 51|1@1+ (1,0) [0|0] "" Vector__XXX
 SG_ error50 : 50|1@1+ (1,0) [0|0] "" Vector__XXX
 SG_ error49 : 49|1@1+ (1,0) [0|0] "" Vector__XXX
 SG_ error48 : 48|1@1+ (1,0) [0|0] "" Vector__XXX
 SG_ error47 : 47|1@1+ (1,0) [0|0] "" Vector__XXX
 SG_ error46 : 46|1@1+ (1,0) [0|0] "" Vector__XXX
 SG_ error45 : 45|1@1+ (1,0) [0|0] "" Vector__XXX
 SG_ error44 : 44|1@1+ (1,0) [0|0] "" Vector__XXX
 SG_ error43 : 43|1@1+ (1,0) [0|0] "" Vector__XXX
 SG_ error42 : 42|1@1+ (1,0) [0|0] "" Vector__XXX
 SG_ error41 : 41|1@1+ (1,0) [0|0] "" Vector__XXX
 SG_ error40 : 40|1@1+ (1,0) [0|0] "" Vector__XXX
 SG_ error39 : 39|1@1+ (1,0) [0|0] "" Vector__XXX
 SG_ error38 : 38|1@1+ (1,0) [0|0] "" Vector__XXX
 SG_ error37 : 37|1@1+ (1,0) [0|0] "" Vector__XXX
 SG_ error36 : 36|1@1+ (1,0) [0|0] "" Vector__XXX
 SG_ error35 : 35|1@1+ (1,0) [0|0] "" Vector__XXX
 SG_ error34 : 34|1@1+ (1,0) [0|0] "" Vector__XXX
 SG_ error33 : 33|1@1+ (1,0) [0|0] "" Vector__XXX
 SG_ error32 : 32|1@1+ (1,0) [0|0] "" Vector__XXX
 SG_ error31 : 31|1@1+ (1,0) [0|0] "" Vector__XXX
 SG_ error30 : 30|1@1+ (1,0) [0|0] "" Vector__XXX
 SG_ error29 : 29|1@1+ (1,0) [0|0] "" Vector__XXX
 SG_ error28 : 28|1@1+ (1,0) [0|0] "" Vector__XXX
 SG_ error27 : 27|1@1+ (1,0) [0|0] "" Vector__XXX
 SG_ error26 : 26|1@1+ (1,0) [0|0] "" Vector__XXX
 SG_ error25 : 25|1@1+ (1,0) [0|0] "" Vector__XXX
 SG_ error24 : 24|1@1+ (1,0) [0|0] "" Vector__XXX
 SG_ error23 : 23|1@1+ (1,0) [0|0] "" Vector__XXX
 SG_ error22 : 22|1@1+ (1,0) [0|0] "" Vector__XXX
 SG_ error21 : 21|1@1+ (1,0) [0|0] "" Vector__XXX
 SG_ error20 : 20|1@1+ (1,0) [0|0] "" Vector__XXX
 SG_ error19 : 19|1@1+ (1,0) [0|0] "" Vector__XXX
 SG_ error18 : 18|1@1+ (1,0) [0|0] "" Vector__XXX
 SG_ error17 : 17|1@1+ (1,0) [0|0] "" Vector__XXX
 SG_ error16 : 16|1@1+ (1,0) [0|0] "" Vector__XXX
 SG_ error15 : 15|1@1+ (1,0) [0|0] "" Vector__XXX
 SG_ error14 : 14|1@1+ (1,0) [0|0] "" Vector__XXX
 SG_ error13 : 13|1@1+ (1,0) [0|0] "" Vector__XXX
 SG_ error12 : 12|1@1+ (1,0) [0|0] "" Vector__XXX
 SG_ error11 : 11|1@1+ (1,0) [0|0] "" Vector__XXX
 SG_ error10 : 10|1@1+ (1,0) [0|0] "" Vector__XXX
 SG_ error9 : 9|1@1+ (1,0) [0|0] "" Vector__XXX
 SG_ error8 : 8|1@1+ (1,0) [0|0] "" Vector__XXX
 SG_ error7 : 7|1@1+ (1,0) [0|0] "" Vector__XXX
 SG_ error6 : 6|1@1+ (1,0) [0|0] "" Vector__XXX
 SG_ error5 : 5|1@1+ (1,0) [0|0] "" Vector__XXX
 SG_ error4 : 4|1@1+ (1,0) [0|0] "" Vector__XXX
 SG_ error3 : 3|1@1+ (1,0) [0|0] "" Vector__XXX
 SG_ error2 : 2|1@1+ (1,0) [0|0] "" Vector__XXX
 SG_ error1 : 1|1@1+ (1,0) [0|0] "" Vector__XXX
 SG_ error0 : 0|1@1+ (1,0) [0|0] "" Vector__XXX

BO_ 212 front_sensor_heartbeat_message: 8 Vector__XXX
 SG_ error63 : 63|1@1+ (1,0) [0|0] "" Vector__XXX
 SG_ error62 : 62|1@1+ (1,0) [0|0] "" Vector__XXX
 SG_ error61 : 61|1@1+ (1,0) [0|0] "" Vector__XXX
 SG_ error60 : 60|1@1+ (1,0) [0|0] "" Vector__XXX
 SG_ error59 : 59|1@1+ (1,0) [0|0] "" Vector__XXX
 SG_ error58 : 58|1@1+ (1,0) [0|0] "" Vector__XXX
 SG_ error57 : 57|1@1+ (1,0) [0|0] "" Vector__XXX
 SG_ error56 : 56|1@1+ (1,0) [0|0] "" Vector__XXX
 SG_ error55 : 55|1@1+ (1,0) [0|0] "" Vector__XXX
 SG_ error54 : 54|1@1+ (1,0) [0|0] "" Vector__XXX
 SG_ error53 : 53|1@1+ (1,0) [0|0] "" Vector__XXX
 SG_ error52 : 52|1@1+ (1,0) [0|0] "" Vector__XXX
 SG_ error51 : 51|1@1+ (1,0) [0|0] "" Vector__XXX
 SG_ error50 : 50|1@1+ (1,0) [0|0] "" Vector__XXX
 SG_ error49 : 49|1@1+ (1,0) [0|0] "" Vector__XXX
 SG_ error48 : 48|1@1+ (1,0) [0|0] "" Vector__XXX
 SG_ error47 : 47|1@1+ (1,0) [0|0] "" Vector__XXX
 SG_ error46 : 46|1@1+ (1,0) [0|0] "" Vector__XXX
 SG_ error45 : 45|1@1+ (1,0) [0|0] "" Vector__XXX
 SG_ error44 : 44|1@1+ (1,0) [0|0] "" Vector__XXX
 SG_ error43 : 43|1@1+ (1,0) [0|0] "" Vector__XXX
 SG_ error42 : 42|1@1+ (1,0) [0|0] "" Vector__XXX
 SG_ error41 : 41|1@1+ (1,0) [0|0] "" Vector__XXX
 SG_ error40 : 40|1@1+ (1,0) [0|0] "" Vector__XXX
 SG_ error39 : 39|1@1+ (1,0) [0|0] "" Vector__XXX
 SG_ error38 : 38|1@1+ (1,0) [0|0] "" Vector__XXX
 SG_ error37 : 37|1@1+ (1,0) [0|0] "" Vector__XXX
 SG_ error36 : 36|1@1+ (1,0) [0|0] "" Vector__XXX
 SG_ error35 : 35|1@1+ (1,0) [0|0] "" Vector__XXX
 SG_ error34 : 34|1@1+ (1,0) [0|0] "" Vector__XXX
 SG_ error33 : 33|1@1+ (1,0) [0|0] "" Vector__XXX
 SG_ error32 : 32|1@1+ (1,0) [0|0] "" Vector__XXX
 SG_ error31 : 31|1@1+ (1,0) [0|0] "" Vector__XXX
 SG_ error30 : 30|1@1+ (1,0) [0|0] "" Vector__XXX
 SG_ error29 : 29|1@1+ (1,0) [0|0] "" Vector__XXX
 SG_ error28 : 28|1@1+ (1,0) [0|0] "" Vector__XXX
 SG_ error27 : 27|1@1+ (1,0) [0|0] "" Vector__XXX
 SG_ error26 : 26|1@1+ (1,0) [0|0] "" Vector__XXX
 SG_ error25 : 25|1@1+ (1,0) [0|0] "" Vector__XXX
 SG_ error24 : 24|1@1+ (1,0) [0|0] "" Vector__XXX
 SG_ error23 : 23|1@1+ (1,0) [0|0] "" Vector__XXX
 SG_ error22 : 22|1@1+ (1,0) [0|0] "" Vector__XXX
 SG_ error21 : 21|1@1+ (1,0) [0|0] "" Vector__XXX
 SG_ error20 : 20|1@1+ (1,0) [0|0] "" Vector__XXX
 SG_ error19 : 19|1@1+ (1,0) [0|0] "" Vector__XXX
 SG_ error18 : 18|1@1+ (1,0) [0|0] "" Vector__XXX
 SG_ error17 : 17|1@1+ (1,0) [0|0] "" Vector__XXX
 SG_ error16 : 16|1@1+ (1,0) [0|0] "" Vector__XXX
 SG_ error15 : 15|1@1+ (1,0) [0|0] "" Vector__XXX
 SG_ error14 : 14|1@1+ (1,0) [0|0] "" Vector__XXX
 SG_ error13 : 13|1@1+ (1,0) [0|0] "" Vector__XXX
 SG_ error12 : 12|1@1+ (1,0) [0|0] "" Vector__XXX
 SG_ error11 : 11|1@1+ (1,0) [0|0] "" Vector__XXX
 SG_ error10 : 10|1@1+ (1,0) [0|0] "" Vector__XXX
 SG_ error9 : 9|1@1+ (1,0) [0|0] "" Vector__XXX
 SG_ error8 : 8|1@1+ (1,0) [0|0] "" Vector__XXX
 SG_ error7 : 7|1@1+ (1,0) [0|0] "" Vector__XXX
 SG_ error6 : 6|1@1+ (1,0) [0|0] "" Vector__XXX
 SG_ error5 : 5|1@1+ (1,0) [0|0] "" Vector__XXX
 SG_ error4 : 4|1@1+ (1,0) [0|0] "" Vector__XXX
 SG_ error3 : 3|1@1+ (1,0) [0|0] "" Vector__XXX
 SG_ error2 : 2|1@1+ (1,0) [0|0] "" Vector__XXX
 SG_ error1 : 1|1@1+ (1,0) [0|0] "" Vector__XXX
 SG_ error0 : 0|1@1+ (1,0) [0|0] "" Vector__XXX

BO_ 213 rear_sensor_heartbeat_message: 8 Vector__XXX
 SG_ error63 : 63|1@1+ (1,0) [0|0] "" Vector__XXX
 SG_ error62 : 62|1@1+ (1,0) [0|0] "" Vector__XXX
 SG_ error61 : 61|1@1+ (1,0) [0|0] "" Vector__XXX
 SG_ error60 : 60|1@1+ (1,0) [0|0] "" Vector__XXX
 SG_ error59 : 59|1@1+ (1,0) [0|0] "" Vector__XXX
 SG_ error58 : 58|1@1+ (1,0) [0|0] "" Vector__XXX
 SG_ error57 : 57|1@1+ (1,0) [0|0] "" Vector__XXX
 SG_ error56 : 56|1@1+ (1,0) [0|0] "" Vector__XXX
 SG_ error55 : 55|1@1+ (1,0) [0|0] "" Vector__XXX
 SG_ error54 : 54|1@1+ (1,0) [0|0] "" Vector__XXX
 SG_ error53 : 53|1@1+ (1,0) [0|0] "" Vector__XXX
 SG_ error52 : 52|1@1+ (1,0) [0|0] "" Vector__XXX
 SG_ error51 : 51|1@1+ (1,0) [0|0] "" Vector__XXX
 SG_ error50 : 50|1@1+ (1,0) [0|0] "" Vector__XXX
 SG_ error49 : 49|1@1+ (1,0) [0|0] "" Vector__XXX
 SG_ error48 : 48|1@1+ (1,0) [0|0] "" Vector__XXX
 SG_ error47 : 47|1@1+ (1,0) [0|0] "" Vector__XXX
 SG_ error46 : 46|1@1+ (1,0) [0|0] "" Vector__XXX
 SG_ error45 : 45|1@1+ (1,0) [0|0] "" Vector__XXX
 SG_ error44 : 44|1@1+ (1,0) [0|0] "" Vector__XXX
 SG_ error43 : 43|1@1+ (1,0) [0|0] "" Vector__XXX
 SG_ error42 : 42|1@1+ (1,0) [0|0] "" Vector__XXX
 SG_ error41 : 41|1@1+ (1,0) [0|0] "" Vector__XXX
 SG_ error40 : 40|1@1+ (1,0) [0|0] "" Vector__XXX
 SG_ error39 : 39|1@1+ (1,0) [0|0] "" Vector__XXX
 SG_ error38 : 38|1@1+ (1,0) [0|0] "" Vector__XXX
 SG_ error37 : 37|1@1+ (1,0) [0|0] "" Vector__XXX
 SG_ error36 : 36|1@1+ (1,0) [0|0] "" Vector__XXX
 SG_ error35 : 35|1@1+ (1,0) [0|0] "" Vector__XXX
 SG_ error34 : 34|1@1+ (1,0) [0|0] "" Vector__XXX
 SG_ error33 : 33|1@1+ (1,0) [0|0] "" Vector__XXX
 SG_ error32 : 32|1@1+ (1,0) [0|0] "" Vector__XXX
 SG_ error31 : 31|1@1+ (1,0) [0|0] "" Vector__XXX
 SG_ error30 : 30|1@1+ (1,0) [0|0] "" Vector__XXX
 SG_ error29 : 29|1@1+ (1,0) [0|0] "" Vector__XXX
 SG_ error28 : 28|1@1+ (1,0) [0|0] "" Vector__XXX
 SG_ error27 : 27|1@1+ (1,0) [0|0] "" Vector__XXX
 SG_ error26 : 26|1@1+ (1,0) [0|0] "" Vector__XXX
 SG_ error25 : 25|1@1+ (1,0) [0|0] "" Vector__XXX
 SG_ error24 : 24|1@1+ (1,0) [0|0] "" Vector__XXX
 SG_ error23 : 23|1@1+ (1,0) [0|0] "" Vector__XXX
 SG_ error22 : 22|1@1+ (1,0) [0|0] "" Vector__XXX
 SG_ error21 : 21|1@1+ (1,0) [0|0] "" Vector__XXX
 SG_ error20 : 20|1@1+ (1,0) [0|0] "" Vector__XXX
 SG_ error19 : 19|1@1+ (1,0) [0|0] "" Vector__XXX
 SG_ error18 : 18|1@1+ (1,0) [0|0] "" Vector__XXX
 SG_ error17 : 17|1@1+ (1,0) [0|0] "" Vector__XXX
 SG_ error16 : 16|1@1+ (1,0) [0|0] "" Vector__XXX
 SG_ error15 : 15|1@1+ (1,0) [0|0] "" Vector__XXX
 SG_ error14 : 14|1@1+ (1,0) [0|0] "" Vector__XXX
 SG_ error13 : 13|1@1+ (1,0) [0|0] "" Vector__XXX
 SG_ error12 : 12|1@1+ (1,0) [0|0] "" Vector__XXX
 SG_ error11 : 11|1@1+ (1,0) [0|0] "" Vector__XXX
 SG_ error10 : 10|1@1+ (1,0) [0|0] "" Vector__XXX
 SG_ error9 : 9|1@1+ (1,0) [0|0] "" Vector__XXX
 SG_ error8 : 8|1@1+ (1,0) [0|0] "" Vector__XXX
 SG_ error7 : 7|1@1+ (1,0) [0|0] "" Vector__XXX
 SG_ error6 : 6|1@1+ (1,0) [0|0] "" Vector__XXX
 SG_ error5 : 5|1@1+ (1,0) [0|0] "" Vector__XXX
 SG_ error4 : 4|1@1+ (1,0) [0|0] "" Vector__XXX
 SG_ error3 : 3|1@1+ (1,0) [0|0] "" Vector__XXX
 SG_ error2 : 2|1@1+ (1,0) [0|0] "" Vector__XXX
 SG_ error1 : 1|1@1+ (1,0) [0|0] "" Vector__XXX
 SG_ error0 : 0|1@1+ (1,0) [0|0] "" Vector__XXX

BO_ 224 FEB_PING_PONG_counter1: 8 Vector__XXX
 SG_ counter : 0|32@1- (1,0) [0|0] "" Vector__XXX

BO_ 225 FEB_PING_PONG_counter2: 8 Vector__XXX
 SG_ counter : 0|32@1- (1,0) [0|0] "" Vector__XXX

BO_ 226 FEB_PING_PONG_counter3: 8 Vector__XXX
 SG_ counter : 0|32@1- (1,0) [0|0] "" Vector__XXX

BO_ 227 FEB_PING_PONG_counter4: 8 Vector__XXX
 SG_ counter : 0|32@1- (1,0) [0|0] "" Vector__XXX

BO_ 255 pcu_raw_acc: 4 Vector__XXX
 SG_ acc1 : 16|16@1+ (1,0) [0|0] "" Vector__XXX
 SG_ acc0 : 0|16@1+ (1,0) [0|0] "" Vector__XXX

CM_ BO_ 0 "BMS message for BMS state.";
CM_ BO_ 1 "BMS message for cell data.";
CM_ BO_ 2 "BMS message for accumulator voltage.";
CM_ BO_ 3 "BMS message for accumulator temperature.";
CM_ BO_ 4 "Accumulator Faults";
CM_ BO_ 9 "PCU brake message";
CM_ BO_ 10 "BSPD message.";
CM_ BO_ 16 "Dash state + buttons and switches";
CM_ BO_ 22 "LVPDB message for voltages of 24v bus and 12v bus";
CM_ BO_ 23 "LVPDB message for currents of LV, SH, LT, BM_L";
CM_ BO_ 24 "LVPDB message for currents of SM, AF1_AF2, CP_RF";
CM_ BO_ 30 "Linear Potentiometer Front.";
CM_ BO_ 31 "Linear Potentiometer Rear.";
CM_ BO_ 32 "Message for front left tire temp data.";
CM_ BO_ 33 "Message for front right tire temp data.";
CM_ BO_ 34 "Message for rear left tire temp data.";
CM_ BO_ 35 "Message for rear right tire temp data.";
CM_ BO_ 36 "Front wheel speeds (uint16, 0.1 RPM/LSB) + direction flags.";
CM_ SG_ 36 wss_dir_flags "bit0: left wheel direction (0=fwd, 1=rev); bit1: right wheel direction";
CM_ BO_ 37 "Wheel speed sensor data for left and right rear wheels.";
CM_ BO_ 38 "IMU acceleration (LSM6DSOX, FS=2g, 0.061 mg/LSB).";
CM_ BO_ 40 "IMU gyro (LSM6DSOX, FS=2000dps, 70 mdps/LSB).";
CM_ BO_ 42 "Magnetometer (LIS3MDL, FS=16gauss, 0.5844 mG/LSB).";
CM_ BO_ 45 "DART message for Tachometer measurements first 4 fan speeds.";
CM_ BO_ 46 "DART message for Tachometer measurements 5th fan speed.";
CM_ BO_ 52 "BBB TPS Chip";
CM_ BO_ 53 "PCU TPS Chip";
CM_ BO_ 54 "Dash TPS Chip";
CM_ BO_ 55 "DCU TPS Chip";
CM_ BO_ 64 "GPS lat/lon as int32 * 1e7 deg (~11mm/LSB globally).";
CM_ BO_ 65 "GPS altitude (cm) + horizontal/vertical DOP (x100).";
CM_ BO_ 66 "GPS speed (0.01 km/h) and course-over-ground (0.01 deg).";
CM_ BO_ 67 "GPS Time data message (UTC).";
CM_ BO_ 68 "GPS Date data message.";
CM_ BO_ 69 "GPS fix quality, satellite counts, validity flags, position DOP.";
CM_ SG_ 69 fix_mode "1=NoFix, 2=2D, 3=3D";
CM_ SG_ 69 fix_type "0=Invalid, 1=GPS, 2=DGPS, 3=PPS";
CM_ BO_ 71 "Fusion AHRS orientation quaternion (w, x, y, z).";
CM_ BO_ 72 "Fusion AHRS Euler angles (0.01 deg/LSB).";
CM_ BO_ 73 "Fusion linear acceleration (gravity removed, body frame, mg).";
CM_ BO_ 74 "Fusion linear acceleration (gravity removed, earth frame, mg).";
CM_ BO_ 75 "Fusion AHRS internal flags + accel/mag rejection errors.";
CM_ SG_ 75 flags "bit0 startup, bit1 angRateRecov, bit2 accelRecov, bit3 magRecov, bit4 accelIgnored, bit5 magIgnored";
CM_ BO_ 76 "LSM6DSOX IMU and LIS3MDL magnetometer die temperatures (0.01 degC/LSB).";
CM_ BO_ 192 "RMS command message.";
CM_ BO_ 193 "RMS parameter message.";
CM_ BO_ 208 "PCU heartbeat";
CM_ BO_ 209 "Dash Heartbeat";
CM_ BO_ 210 "LVPDB Heartbeat";
CM_ BO_ 211 "DCU Heartbeat";
CM_ BO_ 212 "Front Sensor Heartbeat";
CM_ BO_ 213 "Rear Sensor Heartbeat";
CM_ BO_ 224 "PING PONG counter1.";
CM_ BO_ 225 "PING PONG counter2.";
CM_ BO_ 226 "PING PONG counter3.";
CM_ BO_ 227 "PING PONG counter4.";
CM_ BO_ 255 "PCU RAW ACC ADC";
BA_DEF_ BO_  "SystemMessageLongSymbol" STRING ;
BA_DEF_DEF_  "SystemMessageLongSymbol" "";
BA_ "SystemMessageLongSymbol" BO_ 22 "lvpdb_lv_24v_bus_and_12v_bus_voltages";
